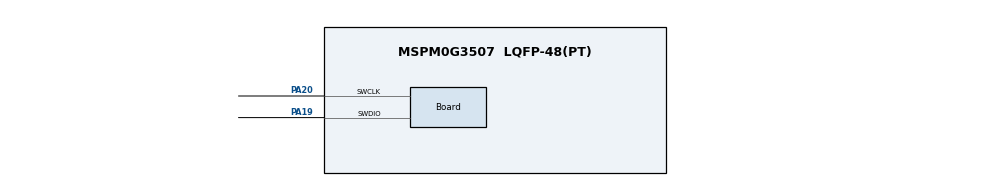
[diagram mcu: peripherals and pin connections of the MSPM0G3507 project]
/**
 * These arguments were used when this file was generated. They will be automatically applied on subsequent loads
 * via the GUI or CLI. Run CLI with '--help' for additional information on how to override these arguments.
 * @cliArgs --device "MSPM0G350X" --part "Default" --package "LQFP-48(PT)" --product "mspm0_sdk@2.04.00.06"
 * @v2CliArgs --device "MSPM0G3507" --package "LQFP-48(PT)" --product "mspm0_sdk@2.04.00.06"
 * @versions {"tool":"1.22.0+3893"}
 */

/**
 * Import the modules used in this configuration.
 */
const GPIO    = scripting.addModule("/ti/driverlib/GPIO", {}, false);
const GPIO1   = GPIO.addInstance();
const GPIO2   = GPIO.addInstance();
const SYSCTL  = scripting.addModule("/ti/driverlib/SYSCTL");
const SYSTICK = scripting.addModule("/ti/driverlib/SYSTICK");

/**
 * Write custom configuration values to the imported modules.
 */
GPIO1.$name                          = "BSL";
GPIO1.associatedPins[0].$name        = "PIN_18";
GPIO1.associatedPins[0].assignedPin  = "18";
GPIO1.associatedPins[0].assignedPort = "PORTA";

const Board                       = scripting.addModule("/ti/driverlib/Board", {}, false);
Board.peripheral.$assign          = "DEBUGSS";
Board.peripheral.swclkPin.$assign = "PA20";
Board.peripheral.swdioPin.$assign = "PA19";

GPIO2.port                           = "PORTA";
GPIO2.$name                          = "I2C";
GPIO2.associatedPins.create(2);
GPIO2.associatedPins[0].$name        = "SCL";
GPIO2.associatedPins[0].initialValue = "SET";
GPIO2.associatedPins[0].assignedPin  = "8";
GPIO2.associatedPins[1].$name        = "SDA";
GPIO2.associatedPins[1].initialValue = "SET";
GPIO2.associatedPins[1].assignedPin  = "9";

SYSCTL.forceDefaultClkConfig = true;
SYSCTL.peripheral.$assign    = "SYSCTL";

SYSTICK.periodEnable      = true;
SYSTICK.period            = 32000;
SYSTICK.interruptEnable   = true;
SYSTICK.systickEnable     = true;
SYSTICK.interruptPriority = "0";

const ProjectConfig              = scripting.addModule("/ti/project_config/ProjectConfig", {}, false);
ProjectConfig.migrationCondition = true;

/**
 * Pinmux solution for unlocked pins/peripherals. This ensures that minor changes to the automatic solver in a future
 * version of the tool will not impact the pinmux you originally saw.  These lines can be completely deleted in order to
 * re-solve from scratch.
 */
GPIO1.associatedPins[0].pin.$suggestSolution = "PA18";
GPIO2.associatedPins[0].pin.$suggestSolution = "PA8";
GPIO2.associatedPins[1].pin.$suggestSolution = "PA9";
